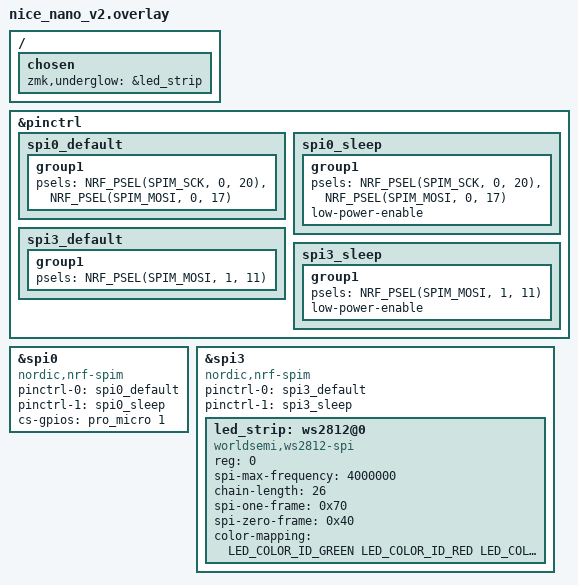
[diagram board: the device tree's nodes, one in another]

/**
 * Generated by Shield Wizard for ZMK
 * Applies to shield "splayt_left" with board "nice_nano_v2" only
 */

//
// ======== spi0 ========
//

// pin control for spi0
// - SCK on D3
// - MOSI on D2
&pinctrl {
    /* configuration for spi0 device, default state */
    spi0_default: spi0_default {
        group1 {
            psels = <NRF_PSEL(SPIM_SCK, 0, 20)>,
                    <NRF_PSEL(SPIM_MOSI, 0, 17)>;
        };
    };
    /* configuration for spi0 device, sleep state */
    spi0_sleep: spi0_sleep {
        group1 {
            psels = <NRF_PSEL(SPIM_SCK, 0, 20)>,
                    <NRF_PSEL(SPIM_MOSI, 0, 17)>;
            low-power-enable;
        };
    };
};
&spi0 {
  compatible = "nordic,nrf-spim";
  status = "okay";
  pinctrl-0 = <&spi0_default>;
  pinctrl-1 = <&spi0_sleep>;
  pinctrl-names = "default", "sleep";
};

// devices on spi0

// CS pins for devices on spi0
&spi0 {
    cs-gpios = <&pro_micro 1 GPIO_ACTIVE_HIGH>;
};

// Label spi0 as nice_view_spi,
// The actual device node is defined in the `nice_view` shield.
nice_view_spi: &spi0 { };

//
// ======== spi3 ========
//

// pin control for spi3
// - MOSI on D14
&pinctrl {
    /* configuration for spi3 device, default state */
    spi3_default: spi3_default {
        group1 {
            psels = <NRF_PSEL(SPIM_MOSI, 1, 11)>;
        };
    };
    /* configuration for spi3 device, sleep state */
    spi3_sleep: spi3_sleep {
        group1 {
            psels = <NRF_PSEL(SPIM_MOSI, 1, 11)>;
            low-power-enable;
        };
    };
};
&spi3 {
  compatible = "nordic,nrf-spim";
  status = "okay";
  pinctrl-0 = <&spi3_default>;
  pinctrl-1 = <&spi3_sleep>;
  pinctrl-names = "default", "sleep";
};

// devices on spi3

#include <dt-bindings/led/led.h>
&spi3 {
    led_strip: ws2812@0 {
        compatible = "worldsemi,ws2812-spi";
        reg = <0>;
        spi-max-frequency = <4000000>;

        chain-length = <26>;
        spi-one-frame = <0x70>;
        spi-zero-frame = <0x40>;
        color-mapping = <LED_COLOR_ID_GREEN
                         LED_COLOR_ID_RED
                         LED_COLOR_ID_BLUE>;
    };
};
/ {
    chosen {
        zmk,underglow = &led_strip;
    };
};
